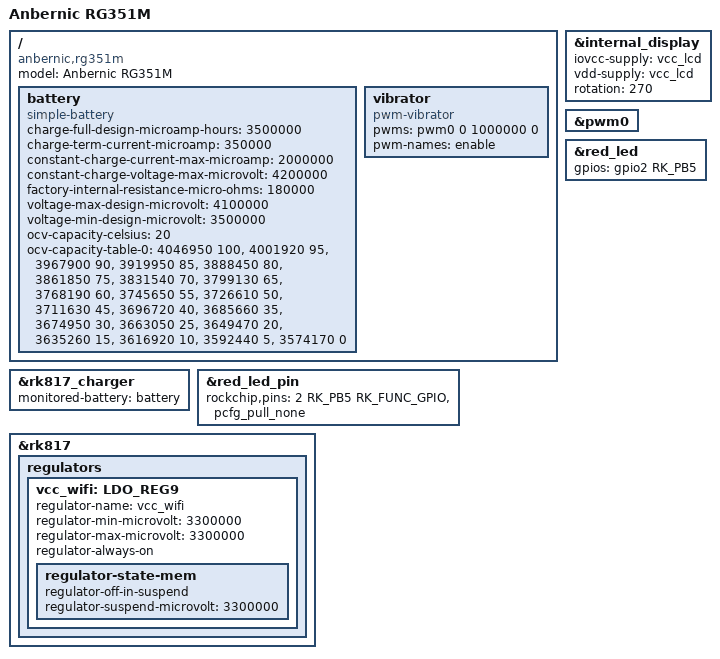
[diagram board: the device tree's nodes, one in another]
// SPDX-License-Identifier: (GPL-2.0+ OR MIT)
/*
 * Copyright (c) 2019 Hardkernel Co., Ltd
 * Copyright (c) 2020 Theobroma Systems Design und Consulting GmbH
 * Copyright (c) 2022 Maya Matuszczyk <maccraft123mc@gmail.com>
 */

/dts-v1/;
#include "rk3326-odroid-go.dtsi"

/ {
	model = "Anbernic RG351M";
	compatible = "anbernic,rg351m", "rockchip,rk3326";

        battery: battery {
               compatible = "simple-battery";
               charge-full-design-microamp-hours = <3500000>;
               charge-term-current-microamp = <350000>;
               constant-charge-current-max-microamp = <2000000>;
               constant-charge-voltage-max-microvolt = <4200000>;
               factory-internal-resistance-micro-ohms = <180000>;
               voltage-max-design-microvolt = <4100000>;
               voltage-min-design-microvolt = <3500000>;

               ocv-capacity-celsius = <20>;
               ocv-capacity-table-0 =  <4046950 100>, <4001920 95>, <3967900 90>, <3919950 85>,
                                       <3888450 80>, <3861850 75>, <3831540 70>, <3799130 65>,
                                       <3768190 60>, <3745650 55>, <3726610 50>, <3711630 45>,
                                       <3696720 40>, <3685660 35>, <3674950 30>, <3663050 25>,
                                       <3649470 20>, <3635260 15>, <3616920 10>, <3592440 5>,
                                       <3574170 0>;
       };

	vibrator {
		compatible = "pwm-vibrator";
		pwms = <&pwm0 0 1000000 0>;
		pwm-names = "enable";
	};
};

/delete-node/ &vcc_host; /* conflicts with pwm vibration motor */

#include "rk3326-panel-elida-kd35t133.dtsi"
&internal_display {
	iovcc-supply = <&vcc_lcd>;
	vdd-supply = <&vcc_lcd>;
	rotation = <270>;
};

&pwm0 {
	status = "okay";
};

&rk817_charger {
       /* This device does not have a current sense resistor */
       //rockchip,resistor-sense-micro-ohms = <0>;
       monitored-battery = <&battery>;
};

/* Per mainline no LED in RG351M */
/delete-node/ &pwm_led;
/delete-node/ &pwm3;

&red_led {
	gpios = <&gpio2 RK_PB5 GPIO_ACTIVE_HIGH>;
};

&red_led_pin {
	rockchip,pins = <2 RK_PB5 RK_FUNC_GPIO &pcfg_pull_none>;
};

&rk817 {
	regulators {
		vcc_wifi: LDO_REG9 {
			regulator-name = "vcc_wifi";
			regulator-min-microvolt = <3300000>;
			regulator-max-microvolt = <3300000>;
			regulator-always-on;

			regulator-state-mem {
				regulator-off-in-suspend;
				regulator-suspend-microvolt = <3300000>;
			};
		};
	};
};
